VERSION ""

NS_ :

BS_:

BU_: BMU BMS VCU

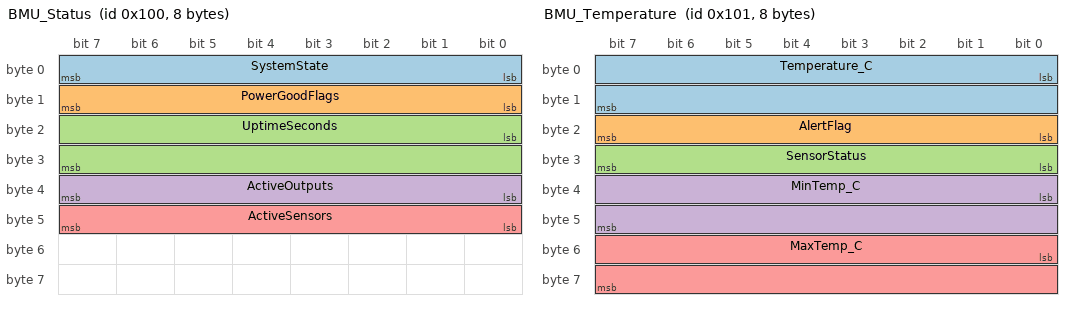
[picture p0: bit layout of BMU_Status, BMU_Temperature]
BO_ 256 BMU_Status: 8 BMU
 SG_ SystemState : 0|8@1+ (1,0) [0|3] "" BMS,VCU
 SG_ PowerGoodFlags : 8|8@1+ (1,0) [0|255] "" BMS,VCU
 SG_ UptimeSeconds : 16|16@1+ (1,0) [0|65535] "s" BMS,VCU
 SG_ ActiveOutputs : 32|8@1+ (1,0) [0|20] "" BMS,VCU
 SG_ ActiveSensors : 40|8@1+ (1,0) [0|10] "" BMS,VCU

BO_ 257 BMU_Temperature: 8 BMU
 SG_ Temperature_C : 0|16@1- (0.01,0) [-100|100] "C" BMS,VCU
 SG_ AlertFlag : 16|8@1+ (1,0) [0|1] "" BMS,VCU
 SG_ SensorStatus : 24|8@1+ (1,0) [0|255] "" BMS,VCU
 SG_ MinTemp_C : 32|16@1- (0.01,0) [-100|100] "C" BMS,VCU
 SG_ MaxTemp_C : 48|16@1- (0.01,0) [-100|100] "C" BMS,VCU

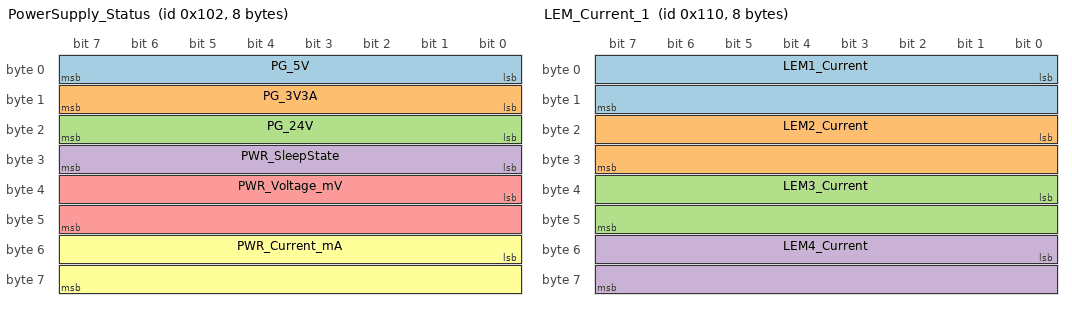
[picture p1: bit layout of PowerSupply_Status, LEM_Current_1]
BO_ 258 PowerSupply_Status: 8 BMU
 SG_ PG_5V : 0|8@1+ (1,0) [0|1] "" BMS,VCU
 SG_ PG_3V3A : 8|8@1+ (1,0) [0|1] "" BMS,VCU
 SG_ PG_24V : 16|8@1+ (1,0) [0|1] "" BMS,VCU
 SG_ PWR_SleepState : 24|8@1+ (1,0) [0|1] "" BMS,VCU
 SG_ PWR_Voltage_mV : 32|16@1+ (1,0) [0|30000] "mV" BMS,VCU
 SG_ PWR_Current_mA : 48|16@1+ (1,0) [0|10000] "mA" BMS,VCU

BO_ 259 Input_States: 8 BMU
 SG_ InputStates : 0|32@1+ (1,0) [0|1048575] "" BMS,VCU

BO_ 272 LEM_Current_1: 8 BMU
 SG_ LEM1_Current : 0|16@1- (0.001,0) [-200|200] "A" BMS,VCU
 SG_ LEM2_Current : 16|16@1- (0.001,0) [-200|200] "A" BMS,VCU
 SG_ LEM3_Current : 32|16@1- (0.001,0) [-200|200] "A" BMS,VCU
 SG_ LEM4_Current : 48|16@1- (0.001,0) [-200|200] "A" BMS,VCU

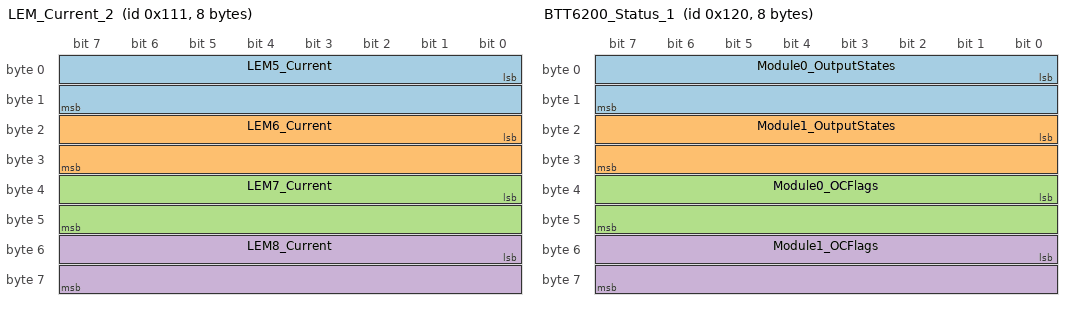
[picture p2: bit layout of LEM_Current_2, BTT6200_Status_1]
BO_ 273 LEM_Current_2: 8 BMU
 SG_ LEM5_Current : 0|16@1- (0.001,0) [-200|200] "A" BMS,VCU
 SG_ LEM6_Current : 16|16@1- (0.001,0) [-200|200] "A" BMS,VCU
 SG_ LEM7_Current : 32|16@1- (0.001,0) [-200|200] "A" BMS,VCU
 SG_ LEM8_Current : 48|16@1- (0.001,0) [-200|200] "A" BMS,VCU

BO_ 274 LEM_Current_3: 8 BMU
 SG_ LEM9_Current : 0|16@1- (0.001,0) [-200|200] "A" BMS,VCU
 SG_ LEM10_Current : 16|16@1- (0.001,0) [-200|200] "A" BMS,VCU

BO_ 288 BTT6200_Status_1: 8 BMU
 SG_ Module0_OutputStates : 0|16@1+ (1,0) [0|15] "" BMS,VCU
 SG_ Module1_OutputStates : 16|16@1+ (1,0) [0|15] "" BMS,VCU
 SG_ Module0_OCFlags : 32|16@1+ (1,0) [0|15] "" BMS,VCU
 SG_ Module1_OCFlags : 48|16@1+ (1,0) [0|15] "" BMS,VCU

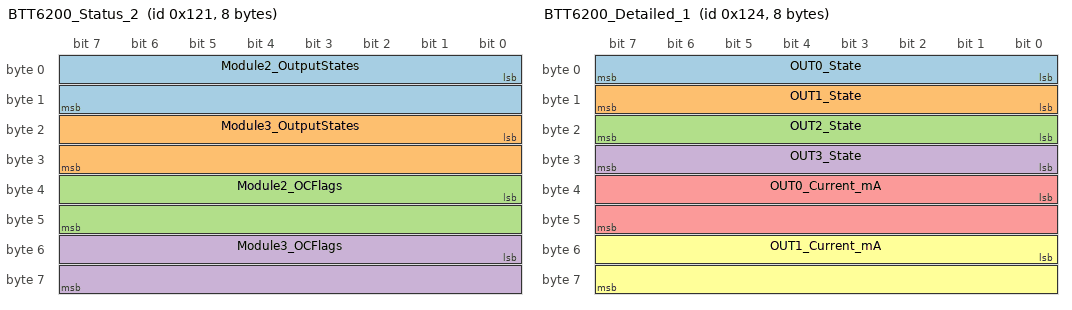
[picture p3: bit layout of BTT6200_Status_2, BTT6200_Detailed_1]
BO_ 289 BTT6200_Status_2: 8 BMU
 SG_ Module2_OutputStates : 0|16@1+ (1,0) [0|15] "" BMS,VCU
 SG_ Module3_OutputStates : 16|16@1+ (1,0) [0|15] "" BMS,VCU
 SG_ Module2_OCFlags : 32|16@1+ (1,0) [0|15] "" BMS,VCU
 SG_ Module3_OCFlags : 48|16@1+ (1,0) [0|15] "" BMS,VCU

BO_ 290 BTT6200_Status_3: 8 BMU
 SG_ Module4_OutputStates : 0|16@1+ (1,0) [0|15] "" BMS,VCU
 SG_ Module4_OCFlags : 16|16@1+ (1,0) [0|15] "" BMS,VCU

BO_ 292 BTT6200_Detailed_1: 8 BMU
 SG_ OUT0_State : 0|8@1+ (1,0) [0|1] "" BMS,VCU
 SG_ OUT1_State : 8|8@1+ (1,0) [0|1] "" BMS,VCU
 SG_ OUT2_State : 16|8@1+ (1,0) [0|1] "" BMS,VCU
 SG_ OUT3_State : 24|8@1+ (1,0) [0|1] "" BMS,VCU
 SG_ OUT0_Current_mA : 32|16@1+ (1,0) [0|10000] "mA" BMS,VCU
 SG_ OUT1_Current_mA : 48|16@1+ (1,0) [0|10000] "mA" BMS,VCU

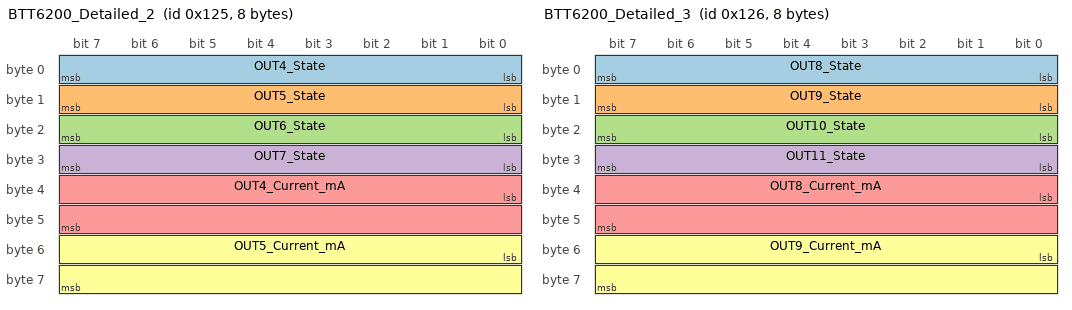
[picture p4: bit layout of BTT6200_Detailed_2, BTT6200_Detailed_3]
BO_ 293 BTT6200_Detailed_2: 8 BMU
 SG_ OUT4_State : 0|8@1+ (1,0) [0|1] "" BMS,VCU
 SG_ OUT5_State : 8|8@1+ (1,0) [0|1] "" BMS,VCU
 SG_ OUT6_State : 16|8@1+ (1,0) [0|1] "" BMS,VCU
 SG_ OUT7_State : 24|8@1+ (1,0) [0|1] "" BMS,VCU
 SG_ OUT4_Current_mA : 32|16@1+ (1,0) [0|10000] "mA" BMS,VCU
 SG_ OUT5_Current_mA : 48|16@1+ (1,0) [0|10000] "mA" BMS,VCU

BO_ 294 BTT6200_Detailed_3: 8 BMU
 SG_ OUT8_State : 0|8@1+ (1,0) [0|1] "" BMS,VCU
 SG_ OUT9_State : 8|8@1+ (1,0) [0|1] "" BMS,VCU
 SG_ OUT10_State : 16|8@1+ (1,0) [0|1] "" BMS,VCU
 SG_ OUT11_State : 24|8@1+ (1,0) [0|1] "" BMS,VCU
 SG_ OUT8_Current_mA : 32|16@1+ (1,0) [0|10000] "mA" BMS,VCU
 SG_ OUT9_Current_mA : 48|16@1+ (1,0) [0|10000] "mA" BMS,VCU

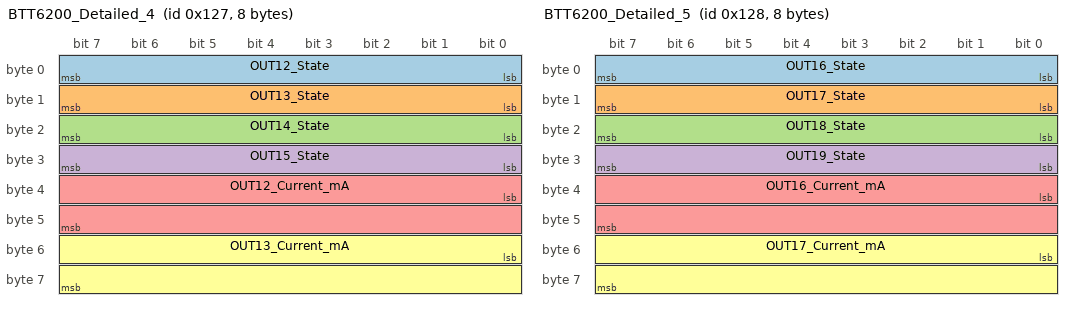
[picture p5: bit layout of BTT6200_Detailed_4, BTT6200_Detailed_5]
BO_ 295 BTT6200_Detailed_4: 8 BMU
 SG_ OUT12_State : 0|8@1+ (1,0) [0|1] "" BMS,VCU
 SG_ OUT13_State : 8|8@1+ (1,0) [0|1] "" BMS,VCU
 SG_ OUT14_State : 16|8@1+ (1,0) [0|1] "" BMS,VCU
 SG_ OUT15_State : 24|8@1+ (1,0) [0|1] "" BMS,VCU
 SG_ OUT12_Current_mA : 32|16@1+ (1,0) [0|10000] "mA" BMS,VCU
 SG_ OUT13_Current_mA : 48|16@1+ (1,0) [0|10000] "mA" BMS,VCU

BO_ 296 BTT6200_Detailed_5: 8 BMU
 SG_ OUT16_State : 0|8@1+ (1,0) [0|1] "" BMS,VCU
 SG_ OUT17_State : 8|8@1+ (1,0) [0|1] "" BMS,VCU
 SG_ OUT18_State : 16|8@1+ (1,0) [0|1] "" BMS,VCU
 SG_ OUT19_State : 24|8@1+ (1,0) [0|1] "" BMS,VCU
 SG_ OUT16_Current_mA : 32|16@1+ (1,0) [0|10000] "mA" BMS,VCU
 SG_ OUT17_Current_mA : 48|16@1+ (1,0) [0|10000] "mA" BMS,VCU

BO_ 291 CAN_Test_Message: 8 BMU
 SG_ TestData : 0|64@1+ (1,0) [0|18446744073709551615] "" BMS,VCU

BO_ 304 FRAM_Statistics: 8 BMU
 SG_ SampleCount : 0|32@1+ (1,0) [0|4294967295] "" BMS,VCU
 SG_ AlertCount : 32|32@1+ (1,0) [0|4294967295] "" BMS,VCU

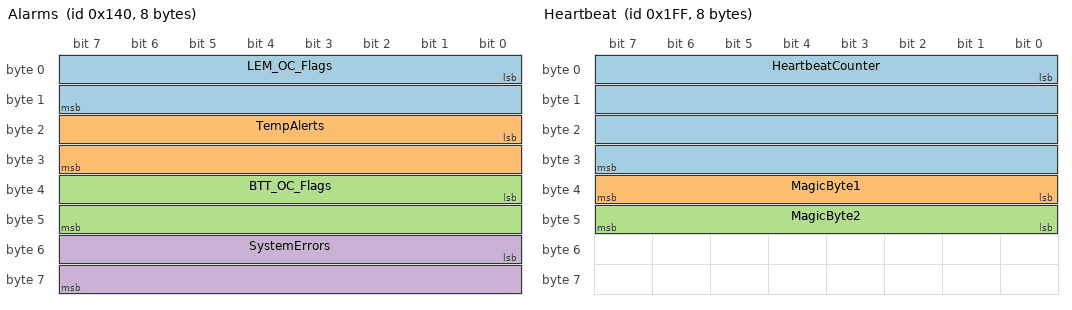
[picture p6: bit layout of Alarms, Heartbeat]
BO_ 320 Alarms: 8 BMU
 SG_ LEM_OC_Flags : 0|16@1+ (1,0) [0|1023] "" BMS,VCU
 SG_ TempAlerts : 16|16@1+ (1,0) [0|65535] "" BMS,VCU
 SG_ BTT_OC_Flags : 32|16@1+ (1,0) [0|65535] "" BMS,VCU
 SG_ SystemErrors : 48|16@1+ (1,0) [0|65535] "" BMS,VCU

BO_ 511 Heartbeat: 8 BMU
 SG_ HeartbeatCounter : 0|32@1+ (1,0) [0|4294967295] "" BMS,VCU
 SG_ MagicByte1 : 32|8@1+ (1,0) [0|255] "" BMS,VCU
 SG_ MagicByte2 : 40|8@1+ (1,0) [0|255] "" BMS,VCU

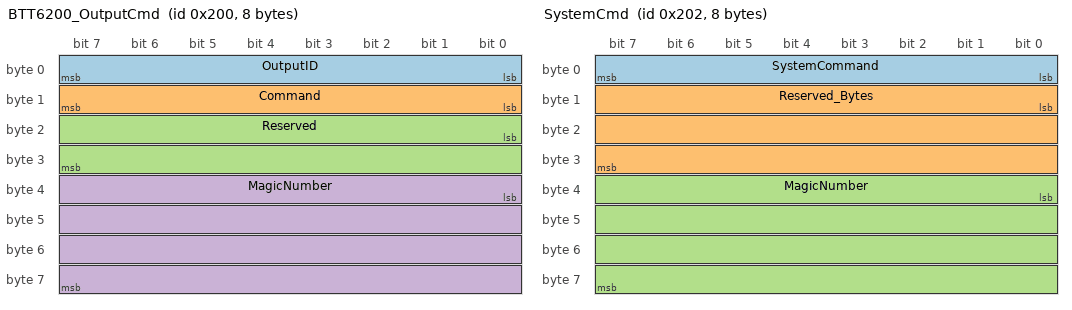
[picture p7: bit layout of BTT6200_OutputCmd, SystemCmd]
BO_ 512 BTT6200_OutputCmd: 8 BMS,VCU
 SG_ OutputID : 0|8@1+ (1,0) [0|19] "" BMU
 SG_ Command : 8|8@1+ (1,0) [0|2] "" BMU
 SG_ Reserved : 16|16@1+ (1,0) [0|65535] "" BMU
 SG_ MagicNumber : 32|32@1+ (1,0) [0|4294967295] "" BMU

BO_ 513 BTT6200_MultiCmd: 8 BMS,VCU
 SG_ OutputMask : 0|32@1+ (1,0) [0|1048575] "" BMU
 SG_ OutputStates : 32|32@1+ (1,0) [0|1048575] "" BMU

BO_ 514 SystemCmd: 8 BMS,VCU
 SG_ SystemCommand : 0|8@1+ (1,0) [0|255] "" BMU
 SG_ Reserved_Bytes : 8|24@1+ (1,0) [0|16777215] "" BMU
 SG_ MagicNumber : 32|32@1+ (1,0) [0|4294967295] "" BMU

BO_ 768 DCDC_Cmd_Conv1: 8 BMS,VCU
 SG_ Command : 0|8@1+ (1,0) [0|1] "" BMU
 SG_ Reserved : 8|56@1+ (1,0) [0|72057594037927935] "" BMU

BO_ 769 DCDC_Cmd_Conv2: 8 BMS,VCU
 SG_ Command : 0|8@1+ (1,0) [0|1] "" BMU
 SG_ Reserved : 8|56@1+ (1,0) [0|72057594037927935] "" BMU

BO_ 770 DCDC_Cmd_Both: 8 BMS,VCU
 SG_ Command : 0|8@1+ (1,0) [0|1] "" BMU
 SG_ Reserved : 8|56@1+ (1,0) [0|72057594037927935] "" BMU

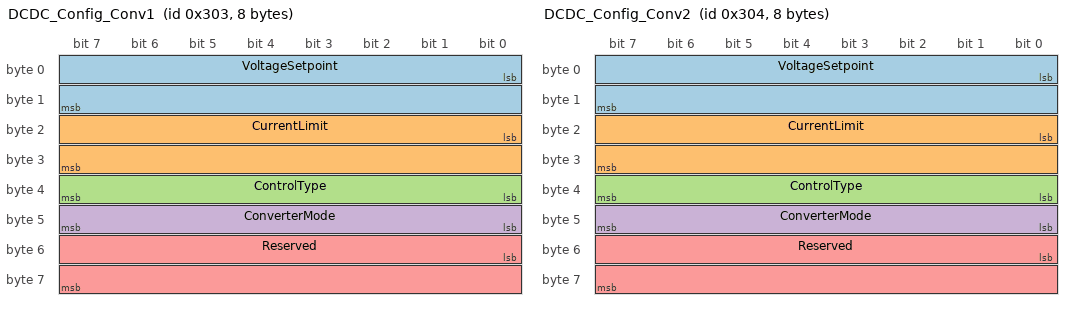
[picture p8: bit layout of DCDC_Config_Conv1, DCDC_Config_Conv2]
BO_ 771 DCDC_Config_Conv1: 8 BMS,VCU
 SG_ VoltageSetpoint : 0|16@1+ (0.1,0) [0|6553.5] "V" BMU
 SG_ CurrentLimit : 16|16@1+ (0.1,0) [0|6553.5] "A" BMU
 SG_ ControlType : 32|8@1+ (1,0) [0|255] "" BMU
 SG_ ConverterMode : 40|8@1+ (1,0) [0|255] "" BMU
 SG_ Reserved : 48|16@1+ (1,0) [0|65535] "" BMU

BO_ 772 DCDC_Config_Conv2: 8 BMS,VCU
 SG_ VoltageSetpoint : 0|16@1+ (0.1,0) [0|6553.5] "V" BMU
 SG_ CurrentLimit : 16|16@1+ (0.1,0) [0|6553.5] "A" BMU
 SG_ ControlType : 32|8@1+ (1,0) [0|255] "" BMU
 SG_ ConverterMode : 40|8@1+ (1,0) [0|255] "" BMU
 SG_ Reserved : 48|16@1+ (1,0) [0|65535] "" BMU

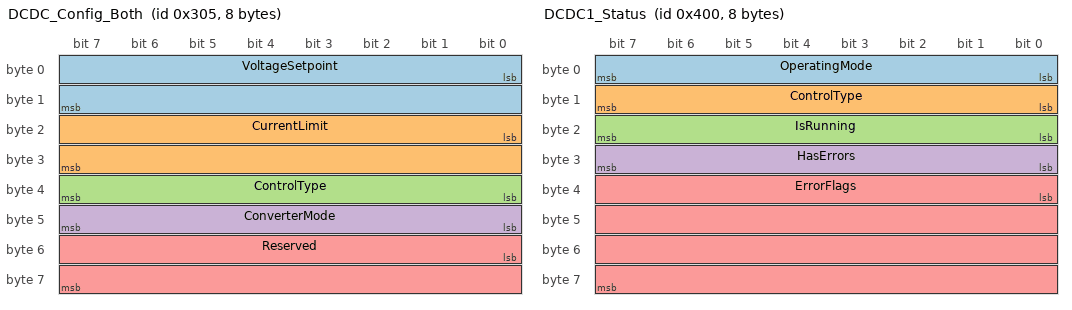
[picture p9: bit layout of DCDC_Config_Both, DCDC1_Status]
BO_ 773 DCDC_Config_Both: 8 BMS,VCU
 SG_ VoltageSetpoint : 0|16@1+ (0.1,0) [0|6553.5] "V" BMU
 SG_ CurrentLimit : 16|16@1+ (0.1,0) [0|6553.5] "A" BMU
 SG_ ControlType : 32|8@1+ (1,0) [0|255] "" BMU
 SG_ ConverterMode : 40|8@1+ (1,0) [0|255] "" BMU
 SG_ Reserved : 48|16@1+ (1,0) [0|65535] "" BMU

BO_ 1024 DCDC1_Status: 8 BMU
 SG_ OperatingMode : 0|8@1+ (1,0) [0|255] "" BMS,VCU
 SG_ ControlType : 8|8@1+ (1,0) [0|255] "" BMS,VCU
 SG_ IsRunning : 16|8@1+ (1,0) [0|1] "" BMS,VCU
 SG_ HasErrors : 24|8@1+ (1,0) [0|1] "" BMS,VCU
 SG_ ErrorFlags : 32|32@1+ (1,0) [0|4294967295] "" BMS,VCU

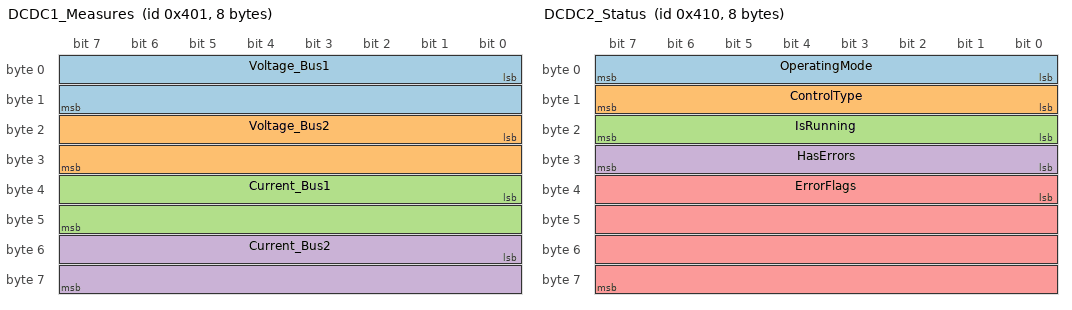
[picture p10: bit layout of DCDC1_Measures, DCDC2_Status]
BO_ 1025 DCDC1_Measures: 8 BMU
 SG_ Voltage_Bus1 : 0|16@1+ (0.1,0) [0|6553.5] "V" BMS,VCU
 SG_ Voltage_Bus2 : 16|16@1+ (0.1,0) [0|6553.5] "V" BMS,VCU
 SG_ Current_Bus1 : 32|16@1- (0.1,0) [-3276.8|3276.7] "A" BMS,VCU
 SG_ Current_Bus2 : 48|16@1- (0.1,0) [-3276.8|3276.7] "A" BMS,VCU

BO_ 1026 DCDC1_Power: 8 BMU
 SG_ Power_Bus1 : 0|32@1+ (1,0) [0|4294967295] "W" BMS,VCU
 SG_ Power_Bus2 : 32|32@1+ (1,0) [0|4294967295] "W" BMS,VCU

BO_ 1040 DCDC2_Status: 8 BMU
 SG_ OperatingMode : 0|8@1+ (1,0) [0|255] "" BMS,VCU
 SG_ ControlType : 8|8@1+ (1,0) [0|255] "" BMS,VCU
 SG_ IsRunning : 16|8@1+ (1,0) [0|1] "" BMS,VCU
 SG_ HasErrors : 24|8@1+ (1,0) [0|1] "" BMS,VCU
 SG_ ErrorFlags : 32|32@1+ (1,0) [0|4294967295] "" BMS,VCU

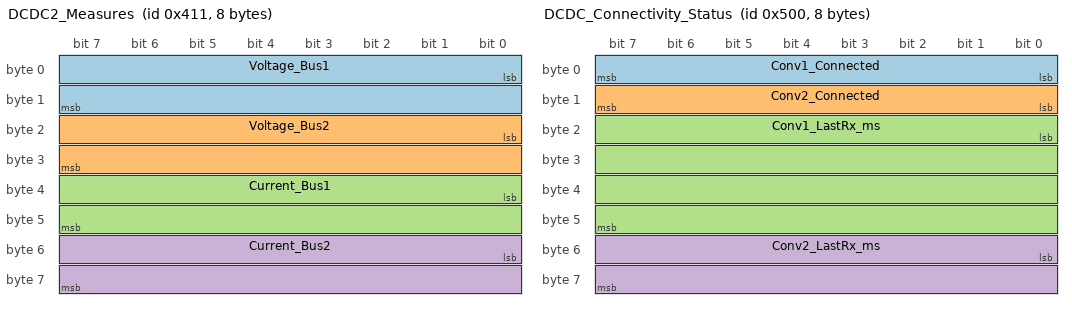
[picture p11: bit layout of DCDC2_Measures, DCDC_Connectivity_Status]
BO_ 1041 DCDC2_Measures: 8 BMU
 SG_ Voltage_Bus1 : 0|16@1+ (0.1,0) [0|6553.5] "V" BMS,VCU
 SG_ Voltage_Bus2 : 16|16@1+ (0.1,0) [0|6553.5] "V" BMS,VCU
 SG_ Current_Bus1 : 32|16@1- (0.1,0) [-3276.8|3276.7] "A" BMS,VCU
 SG_ Current_Bus2 : 48|16@1- (0.1,0) [-3276.8|3276.7] "A" BMS,VCU

BO_ 1042 DCDC2_Power: 8 BMU
 SG_ Power_Bus1 : 0|32@1+ (1,0) [0|4294967295] "W" BMS,VCU
 SG_ Power_Bus2 : 32|32@1+ (1,0) [0|4294967295] "W" BMS,VCU

BO_ 1280 DCDC_Connectivity_Status: 8 BMU
 SG_ Conv1_Connected : 0|8@1+ (1,0) [0|1] "" BMS,VCU
 SG_ Conv2_Connected : 8|8@1+ (1,0) [0|1] "" BMS,VCU
 SG_ Conv1_LastRx_ms : 16|32@1+ (1,0) [0|4294967295] "ms" BMS,VCU
 SG_ Conv2_LastRx_ms : 48|16@1+ (1,0) [0|65535] "ms" BMS,VCU

CM_ BU_ BMU "Battery Management Unit - Main Controller";
CM_ BU_ BMS "Battery Management System - External";
CM_ BU_ VCU "Vehicle Control Unit";
CM_ BO_ 256 "BMU System Status Message - 10Hz";
CM_ BO_ 257 "Temperature Sensor Data - 1Hz";
CM_ BO_ 258 "Power Supply Status (5V, 3.3V, 24V) - 1Hz";
CM_ BO_ 259 "Digital Input States (IN_1 to IN_20) - 1Hz";
CM_ BO_ 272 "LEM Current Sensors 1-4 - 10Hz";
CM_ BO_ 273 "LEM Current Sensors 5-8 - 10Hz";
CM_ BO_ 274 "LEM Current Sensors 9-10 - 10Hz";
CM_ BO_ 288 "BTT6200 Output Status Modules 0-1 - 5Hz";
CM_ BO_ 289 "BTT6200 Output Status Modules 2-3 - 5Hz";
CM_ BO_ 290 "BTT6200 Output Status Module 4 - 5Hz";
CM_ BO_ 292 "BTT6200 Detailed Status OUT 0-3 - 1Hz";
CM_ BO_ 293 "BTT6200 Detailed Status OUT 4-7 - 1Hz";
CM_ BO_ 294 "BTT6200 Detailed Status OUT 8-11 - 1Hz";
CM_ BO_ 295 "BTT6200 Detailed Status OUT 12-15 - 1Hz";
CM_ BO_ 296 "BTT6200 Detailed Status OUT 16-19 - 1Hz";
CM_ BO_ 291 "CAN Test Message - Standard ID 0x123";
CM_ BO_ 304 "FRAM Memory Statistics - 1Hz";
CM_ BO_ 320 "System Alarms and Errors - On Change";
CM_ BO_ 511 "Heartbeat Message - 1Hz";
CM_ BO_ 512 "BTT6200 Output Control Command (RX) - On Demand";
CM_ BO_ 513 "BTT6200 Multiple Output Control (RX) - On Demand";
CM_ BO_ 514 "System Command (RX) - On Demand";
CM_ BO_ 768 "DC/DC Converter 1 ON/OFF Command (RX) - On Demand";
CM_ BO_ 769 "DC/DC Converter 2 ON/OFF Command (RX) - On Demand";
CM_ BO_ 770 "DC/DC Both Converters ON/OFF Command (RX) - On Demand";
CM_ BO_ 771 "DC/DC Converter 1 Configuration (RX) - On Demand";
CM_ BO_ 772 "DC/DC Converter 2 Configuration (RX) - On Demand";
CM_ BO_ 773 "DC/DC Both Converters Configuration (RX) - On Demand";
CM_ BO_ 1024 "DC/DC Converter 1 Status - 10Hz";
CM_ BO_ 1025 "DC/DC Converter 1 Voltage/Current Measurements - 10Hz";
CM_ BO_ 1026 "DC/DC Converter 1 Power Measurements - 10Hz";
CM_ BO_ 1040 "DC/DC Converter 2 Status - 10Hz";
CM_ BO_ 1041 "DC/DC Converter 2 Voltage/Current Measurements - 10Hz";
CM_ BO_ 1042 "DC/DC Converter 2 Power Measurements - 10Hz";
CM_ BO_ 1280 "DC/DC Connectivity Status - 10Hz (Shows if converters are responding on CAN2)";
CM_ SG_ 256 SystemState "0=Init, 1=Normal, 2=Warning, 3=Error";
CM_ SG_ 256 PowerGoodFlags "Bit0=5V, Bit1=3V3A, Bit2=24V";
CM_ SG_ 257 Temperature_C "Current temperature from TMP1075 sensor";
CM_ SG_ 257 AlertFlag "1=Temperature below 0C";
CM_ SG_ 272 LEM1_Current "LEM sensor 1 current measurement in Amperes";
CM_ SG_ 272 LEM2_Current "LEM sensor 2 current measurement in Amperes";
CM_ SG_ 272 LEM3_Current "LEM sensor 3 current measurement in Amperes";
CM_ SG_ 272 LEM4_Current "LEM sensor 4 current measurement in Amperes";
CM_ SG_ 320 LEM_OC_Flags "LEM Overcurrent flags: Bit0=LEM1, Bit1=LEM2, etc";
CM_ SG_ 320 SystemErrors "System error flags bitfield";
BA_DEF_ "BusType" STRING ;
BA_DEF_ BO_ "GenMsgCycleTime" INT 0 10000;
BA_DEF_DEF_ "BusType" "CAN";
BA_DEF_DEF_ BO_ "GenMsgCycleTime" 0;
BA_ "GenMsgCycleTime" BO_ 256 100;
BA_ "GenMsgCycleTime" BO_ 257 1000;
BA_ "GenMsgCycleTime" BO_ 258 1000;
BA_ "GenMsgCycleTime" BO_ 259 1000;
BA_ "GenMsgCycleTime" BO_ 272 100;
BA_ "GenMsgCycleTime" BO_ 273 100;
BA_ "GenMsgCycleTime" BO_ 274 100;
BA_ "GenMsgCycleTime" BO_ 288 200;
BA_ "GenMsgCycleTime" BO_ 289 200;
BA_ "GenMsgCycleTime" BO_ 290 200;
BA_ "GenMsgCycleTime" BO_ 292 1000;
BA_ "GenMsgCycleTime" BO_ 293 1000;
BA_ "GenMsgCycleTime" BO_ 294 1000;
BA_ "GenMsgCycleTime" BO_ 295 1000;
BA_ "GenMsgCycleTime" BO_ 296 1000;
BA_ "GenMsgCycleTime" BO_ 304 1000;
BA_ "GenMsgCycleTime" BO_ 320 0;
BA_ "GenMsgCycleTime" BO_ 511 1000;
BA_ "GenMsgCycleTime" BO_ 512 0;
BA_ "GenMsgCycleTime" BO_ 513 0;
BA_ "GenMsgCycleTime" BO_ 514 0;
BA_ "GenMsgCycleTime" BO_ 291 0;
BA_ "GenMsgCycleTime" BO_ 768 0;
BA_ "GenMsgCycleTime" BO_ 769 0;
BA_ "GenMsgCycleTime" BO_ 770 0;
BA_ "GenMsgCycleTime" BO_ 771 0;
BA_ "GenMsgCycleTime" BO_ 772 0;
BA_ "GenMsgCycleTime" BO_ 773 0;
BA_ "GenMsgCycleTime" BO_ 1024 100;
BA_ "GenMsgCycleTime" BO_ 1025 100;
BA_ "GenMsgCycleTime" BO_ 1026 100;
BA_ "GenMsgCycleTime" BO_ 1040 100;
BA_ "GenMsgCycleTime" BO_ 1041 100;
BA_ "GenMsgCycleTime" BO_ 1042 100;
BA_ "GenMsgCycleTime" BO_ 1280 100;
VAL_ 256 SystemState 0 "Init" 1 "Normal" 2 "Warning" 3 "Error" ;
VAL_ 257 AlertFlag 0 "OK" 1 "LowTempAlert" ;
VAL_ 258 PG_5V 0 "Fault" 1 "OK" ;
VAL_ 258 PG_3V3A 0 "Fault" 1 "OK" ;
VAL_ 258 PG_24V 0 "Fault" 1 "OK" ;
VAL_ 512 Command 0 "OFF" 1 "ON" 2 "TOGGLE" ;
VAL_ 514 SystemCommand 0 "NOP" 1 "RESET_STATS" 2 "DISABLE_ALL" 3 "ENABLE_ALL" 254 "REBOOT" ;
VAL_ 768 Command 0 "OFF" 1 "ON" ;
VAL_ 769 Command 0 "OFF" 1 "ON" ;
VAL_ 770 Command 0 "OFF" 1 "ON" ;
VAL_ 771 ControlType 7 "vBus2Lim" 8 "vBus1Lim" ;
VAL_ 771 ConverterMode 0 "Standby" 1 "Bus1toBus2" 2 "Bus2toBus1" ;
VAL_ 772 ControlType 7 "vBus2Lim" 8 "vBus1Lim" ;
VAL_ 772 ConverterMode 0 "Standby" 1 "Bus1toBus2" 2 "Bus2toBus1" ;
VAL_ 773 ControlType 7 "vBus2Lim" 8 "vBus1Lim" ;
VAL_ 773 ConverterMode 0 "Standby" 1 "Bus1toBus2" 2 "Bus2toBus1" ;
VAL_ 1024 OperatingMode 0 "Standby" 1 "Bus1toBus2" 2 "Bus2toBus1" ;
VAL_ 1024 ControlType 7 "vBus2Lim" 8 "vBus1Lim" ;
VAL_ 1024 IsRunning 0 "Stopped" 1 "Running" ;
VAL_ 1024 HasErrors 0 "NoErrors" 1 "HasErrors" ;
VAL_ 1040 OperatingMode 0 "Standby" 1 "Bus1toBus2" 2 "Bus2toBus1" ;
VAL_ 1040 ControlType 7 "vBus2Lim" 8 "vBus1Lim" ;
VAL_ 1040 IsRunning 0 "Stopped" 1 "Running" ;
VAL_ 1040 HasErrors 0 "NoErrors" 1 "HasErrors" ;
